AUTOSAR XML (schema 00046)
package /ComponentTypes
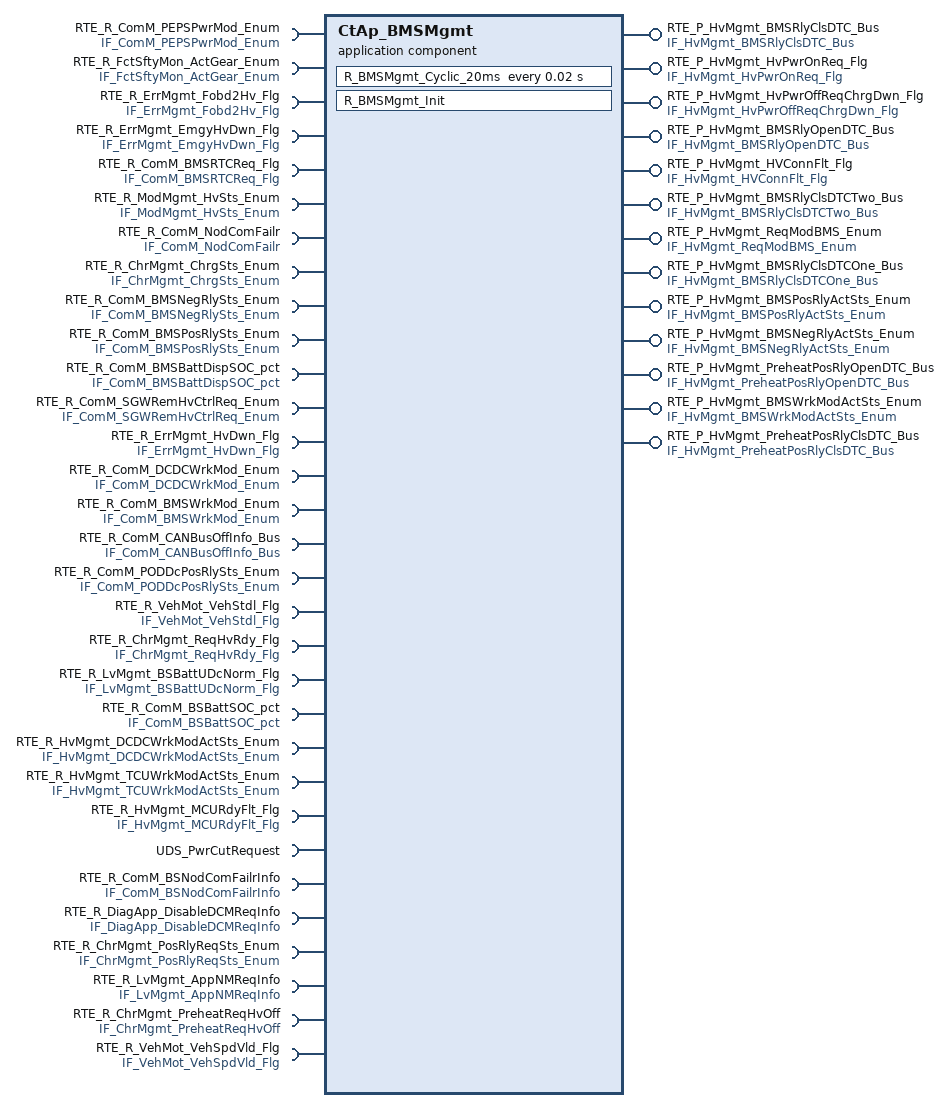
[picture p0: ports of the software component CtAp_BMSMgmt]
  application sw component type CtAp_BMSMgmt
    21 x require port:
      RTE_R_ComM_PEPSPwrMod_Enum: nonqueued-receiver-com-spec{data-element=tec_ComM_PEPSPwrMod_Enum, filter=data-filter-type=ALWAYS, init-value=0}, required-interface=IF_ComM_PEPSPwrMod_Enum
      RTE_R_FctSftyMon_ActGear_Enum: nonqueued-receiver-com-spec{data-element=tec_FctSftyMon_ActGear_Enum, filter=data-filter-type=ALWAYS, init-value=0}, required-interface=IF_FctSftyMon_ActGear_Enum
      RTE_R_ErrMgmt_Fobd2Hv_Flg: nonqueued-receiver-com-spec{data-element=tec_ErrMgmt_Fobd2Hv_Flg, filter=data-filter-type=ALWAYS, init-value=0}, required-interface=IF_ErrMgmt_Fobd2Hv_Flg
      RTE_R_ErrMgmt_EmgyHvDwn_Flg: nonqueued-receiver-com-spec{data-element=tec_ErrMgmt_EmgyHvDwn_Flg, filter=data-filter-type=ALWAYS, init-value=0}, required-interface=IF_ErrMgmt_EmgyHvDwn_Flg
      RTE_R_ComM_BMSRTCReq_Flg: nonqueued-receiver-com-spec{data-element=tec_ComM_BMSRTCReq_Flg, filter=data-filter-type=ALWAYS, init-value=0}, required-interface=IF_ComM_BMSRTCReq_Flg
      RTE_R_ModMgmt_HvSts_Enum: nonqueued-receiver-com-spec{data-element=tec_ModMgmt_HvSts_Enum, filter=data-filter-type=ALWAYS, init-value=0}, required-interface=IF_ModMgmt_HvSts_Enum
      RTE_R_ComM_NodComFailr: required-interface=IF_ComM_NodComFailr
        required-com-specs:
          data-element=tec_ComM_SGWNodComFailr_Flg, filter=data-filter-type=ALWAYS, init-value=0
          data-element=tec_ComM_CGWNodComFailr_Flg, filter=data-filter-type=ALWAYS, init-value=0
          data-element=tec_ComM_TCUNodComFailr_Flg, filter=data-filter-type=ALWAYS, init-value=0
          data-element=tec_ComM_BCMNodComFailr_Flg, filter=data-filter-type=ALWAYS, init-value=0
          data-element=tec_ComM_PRNDNodComFailr_Flg, filter=data-filter-type=ALWAYS, init-value=0
          data-element=tec_ComM_IVINodComFailr_Flg, filter=data-filter-type=ALWAYS, init-value=0
          data-element=tec_ComM_DCDCNodComFailr_Flg, filter=data-filter-type=ALWAYS, init-value=0
          data-element=tec_ComM_OBCNodComFailr_Flg, filter=data-filter-type=ALWAYS, init-value=0
          data-element=tec_ComM_CHIBSNodComFailr_Flg, filter=data-filter-type=ALWAYS, init-value=0
          data-element=tec_ComM_MCUNodComFailr_Flg, filter=data-filter-type=ALWAYS, init-value=0
          data-element=tec_ComM_EVCOMNodComFailr_Flg, filter=data-filter-type=ALWAYS, init-value=0
          data-element=tec_ComM_EPTIBSNodComFailr_Flg, filter=data-filter-type=ALWAYS, init-value=0
          data-element=tec_ComM_DCMNodComFailr_Flg, filter=data-filter-type=ALWAYS, init-value=0
          data-element=tec_ComM_BMSNodComFailr_Flg, filter=data-filter-type=ALWAYS, init-value=0
          data-element=tec_ComM_ACUNodComFailr_Flg, filter=data-filter-type=ALWAYS, init-value=0
          data-element=tec_ComM_APTCNodComFailr_Flg, filter=data-filter-type=ALWAYS, init-value=0
          data-element=tec_ComM_ADCUNodComFailr_Flg, filter=data-filter-type=ALWAYS, init-value=0
          data-element=tec_ComM_DCMRRNodComFailr_Flg, filter=data-filter-type=ALWAYS, init-value=0
          data-element=tec_ComM_DCMRLNodComFailr_Flg, filter=data-filter-type=ALWAYS, init-value=0
          data-element=tec_ComM_DCMFRNodComFailr_Flg, filter=data-filter-type=ALWAYS, init-value=0
          data-element=tec_ComM_DCMFLNodComFailr_Flg, filter=data-filter-type=ALWAYS, init-value=0
          data-element=tec_ComM_SGWCHNodComFailr_Flg, init-value=0
      RTE_R_ChrMgmt_ChrgSts_Enum: nonqueued-receiver-com-spec{data-element=tec_ChrMgmt_ChrgSts_Enum, filter=data-filter-type=ALWAYS, init-value=0}, required-interface=IF_ChrMgmt_ChrgSts_Enum
      RTE_R_ComM_BMSNegRlySts_Enum: nonqueued-receiver-com-spec{data-element=tec_ComM_BMSNegRlySts_Enum, filter=data-filter-type=ALWAYS, init-value=0}, required-interface=IF_ComM_BMSNegRlySts_Enum
      RTE_R_ComM_BMSPosRlySts_Enum: nonqueued-receiver-com-spec{data-element=tec_ComM_BMSPosRlySts_Enum, filter=data-filter-type=ALWAYS, init-value=0}, required-interface=IF_ComM_BMSPosRlySts_Enum
      RTE_R_ComM_BMSBattDispSOC_pct: nonqueued-receiver-com-spec{data-element=tec_ComM_BMSBattDispSOC_pct, filter=data-filter-type=ALWAYS, init-value=0}, required-interface=IF_ComM_BMSBattDispSOC_pct
      RTE_R_ComM_SGWRemHvCtrlReq_Enum: nonqueued-receiver-com-spec{data-element=tec_ComM_SGWRemHvCtrlReq_Enum, filter=data-filter-type=ALWAYS, init-value=0}, required-interface=IF_ComM_SGWRemHvCtrlReq_Enum
      RTE_R_ErrMgmt_HvDwn_Flg: nonqueued-receiver-com-spec{data-element=tec_ErrMgmt_HvDwn_Flg, filter=data-filter-type=ALWAYS, init-value=0}, required-interface=IF_ErrMgmt_HvDwn_Flg
      RTE_R_ComM_DCDCWrkMod_Enum: nonqueued-receiver-com-spec{data-element=tec_ComM_DCDCWrkMod_Enum, filter=data-filter-type=ALWAYS, init-value=0}, required-interface=IF_ComM_DCDCWrkMod_Enum
      RTE_R_ComM_BMSWrkMod_Enum: nonqueued-receiver-com-spec{data-element=tec_ComM_BMSWrkMod_Enum, filter=data-filter-type=ALWAYS, init-value=0}, required-interface=IF_ComM_BMSWrkMod_Enum
      RTE_R_ComM_CANBusOffInfo_Bus: required-interface=IF_ComM_CANBusOffInfo_Bus
        required-com-specs:
          data-element=tec_ComM_EPTCANBusOffInfo_Bus, filter=data-filter-type=ALWAYS, init-value=fields=[ComM_MonStatEPTCANBusOffInfo:0, ComM_MonResEPTCANBusOffInfo:0, ComM_ErrStatEPTCANBusOffInfo:0, ComM_ErrResEPTCANBusOffInfo:0]
          data-element=tec_ComM_CHCANBusOffInfo_Bus, filter=data-filter-type=ALWAYS, init-value=fields=[ComM_MonStatCHCANBusOffInfo:0, ComM_MonResCHCANBusOffInfo:0, ComM_ErrStatCHCANBusOffInfo:0, ComM_ErrResCHCANBusOffInfo:0]
          data-element=tec_ComM_EPTCANBusOffDTCInfo_Bus, filter=data-filter-type=ALWAYS, init-value=fields=[ComM_MonStatEPTCANBusOffDTCInfo:0, ComM_MonResEPTCANBusOffDTCInfo:0, ComM_ErrStatEPTCANBusOffDTCInfo:0, ComM_ErrResEPTCANBusOffDTCInfo:0]
          data-element=tec_ComM_CHCANBusOffDTCInfo_Bus, filter=data-filter-type=ALWAYS, init-value=fields=[ComM_MonStatCHCANBusOffDTCInfo:0, ComM_MonResCHCANBusOffDTCInfo:0, ComM_ErrStatCHCANBusOffDTCInfo:0, ComM_ErrResCHCANBusOffDTCInfo:0]
          data-element=tec_ComM_DCCANBusOffDTCInfo_Bus, init-value=fields=[ComM_MonStatDCCANDTCBusOffInfo:0, ComM_MonResDCCANDTCBusOffInfo:0, ComM_ErrStatDCCANDTCBusOffInfo:0, ComM_ErrResDCCANDTCBusOffInfo:0]
          data-element=tec_ComM_DCCANBusOffInfo_Bus, init-value=fields=[ComM_MonStatDCCANBusOffInfo:0, ComM_MonResDCCANBusOffInfo:0, ComM_ErrStatDCCANBusOffInfo:0, ComM_ErrResDCCANBusOffInfo:0]
      RTE_R_ComM_PODDcPosRlySts_Enum: nonqueued-receiver-com-spec{data-element=tec_ComM_PODDcPosRlySts_Enum, filter=data-filter-type=ALWAYS, init-value=0}, required-interface=IF_ComM_PODDcPosRlySts_Enum
      RTE_R_VehMot_VehStdl_Flg: nonqueued-receiver-com-spec{data-element=tec_VehMot_VehStdl_Flg, filter=data-filter-type=ALWAYS, init-value=0}, required-interface=IF_VehMot_VehStdl_Flg
      RTE_R_ChrMgmt_ReqHvRdy_Flg: nonqueued-receiver-com-spec{data-element=tec_ChrMgmt_ReqHvRdy_Flg, filter=data-filter-type=ALWAYS, init-value=0}, required-interface=IF_ChrMgmt_ReqHvRdy_Flg
      RTE_R_LvMgmt_BSBattUDcNorm_Flg: nonqueued-receiver-com-spec{data-element=tec_LvMgmt_BSBattUDcNorm_Flg, filter=data-filter-type=ALWAYS, init-value=0}, required-interface=IF_LvMgmt_BSBattUDcNorm_Flg
      RTE_R_ComM_BSBattSOC_pct: nonqueued-receiver-com-spec{data-element=tec_ComM_BSBattSOC_pct, filter=data-filter-type=ALWAYS, init-value=0}, required-interface=IF_ComM_BSBattSOC_pct
    13 x provide port:
      RTE_P_HvMgmt_BMSRlyClsDTC_Bus: nonqueued-sender-com-spec{data-element=tec_HvMgmt_BMSRlyClsDTC_Bus, init-value=fields=[HvMgmt_MonStatBMSRlyClsDTC:0, HvMgmt_MonResBMSRlyClsDTC:0, HvMgmt_ErrStatBMSRlyClsDTC:0, HvMgmt_ErrResBMSRlyClsDTC:0]}, provided-interface=IF_HvMgmt_BMSRlyClsDTC_Bus
      RTE_P_HvMgmt_HvPwrOnReq_Flg: nonqueued-sender-com-spec{data-element=tec_HvMgmt_HvPwrOnReq_Flg, init-value=0}, provided-interface=IF_HvMgmt_HvPwrOnReq_Flg
      RTE_P_HvMgmt_HvPwrOffReqChrgDwn_Flg: nonqueued-sender-com-spec{data-element=tec_HvMgmt_HvPwrOffReqChrgDwn_Flg, init-value=0}, provided-interface=IF_HvMgmt_HvPwrOffReqChrgDwn_Flg
      RTE_P_HvMgmt_BMSRlyOpenDTC_Bus: nonqueued-sender-com-spec{data-element=tec_HvMgmt_BMSRlyOpenDTC_Bus, init-value=fields=[HvMgmt_MonStatBMSRlyOpenDTC:0, HvMgmt_MonResBMSRlyOpenDTC:0, HvMgmt_ErrStatBMSRlyOpenDTC:0, HvMgmt_ErrResBMSRlyOpenDTC:0]}, provided-interface=IF_HvMgmt_BMSRlyOpenDTC_Bus
      RTE_P_HvMgmt_HVConnFlt_Flg: nonqueued-sender-com-spec{data-element=tec_HvMgmt_HVConnFlt_Flg, init-value=0}, provided-interface=IF_HvMgmt_HVConnFlt_Flg
      RTE_P_HvMgmt_BMSRlyClsDTCTwo_Bus: nonqueued-sender-com-spec{data-element=tec_HvMgmt_BMSRlyClsDTCTwo_Bus, init-value=fields=[HvMgmt_MonStatBMSRlyClsDTCTwo:0, HvMgmt_MonResBMSRlyClsDTCTwo:0, HvMgmt_ErrStatBMSRlyClsDTCTwo:0, HvMgmt_ErrResBMSRlyClsDTCTwo:0]}, provided-interface=IF_HvMgmt_BMSRlyClsDTCTwo_Bus
      RTE_P_HvMgmt_ReqModBMS_Enum: nonqueued-sender-com-spec{data-element=tec_HvMgmt_ReqModBMS_Enum, init-value=0}, provided-interface=IF_HvMgmt_ReqModBMS_Enum
      RTE_P_HvMgmt_BMSRlyClsDTCOne_Bus: nonqueued-sender-com-spec{data-element=tec_HvMgmt_BMSRlyClsDTCOne_Bus, init-value=fields=[HvMgmt_MonStatBMSRlyClsDTCOne:0, HvMgmt_MonResBMSRlyClsDTCOne:0, HvMgmt_ErrStatBMSRlyClsDTCOne:0, HvMgmt_ErrResBMSRlyClsDTCOne:0]}, provided-interface=IF_HvMgmt_BMSRlyClsDTCOne_Bus
      RTE_P_HvMgmt_BMSPosRlyActSts_Enum: nonqueued-sender-com-spec{data-element=tec_HvMgmt_BMSPosRlyActSts_Enum, init-value=0}, provided-interface=IF_HvMgmt_BMSPosRlyActSts_Enum
      RTE_P_HvMgmt_BMSNegRlyActSts_Enum: nonqueued-sender-com-spec{data-element=tec_HvMgmt_BMSNegRlyActSts_Enum, init-value=0}, provided-interface=IF_HvMgmt_BMSNegRlyActSts_Enum
      RTE_P_HvMgmt_PreheatPosRlyOpenDTC_Bus: nonqueued-sender-com-spec{data-element=tec_HvMgmt_PreheatPosRlyOpenDTC_Bus, init-value=fields=[HvMgmt_MonStatPreheatPosRlyOpenDTC:0, HvMgmt_MonResPreheatPosRlyOpenDTC:0, HvMgmt_ErrStatPreheatPosRlyOpenDTC:0, HvMgmt_ErrResPreheatPosRlyOpenDTC:0]}, provided-interface=IF_HvMgmt_PreheatPosRlyOpenDTC_Bus
      RTE_P_HvMgmt_BMSWrkModActSts_Enum: nonqueued-sender-com-spec{data-element=tec_HvMgmt_BMSWrkModActSts_Enum, init-value=0}, provided-interface=IF_HvMgmt_BMSWrkModActSts_Enum
      RTE_P_HvMgmt_PreheatPosRlyClsDTC_Bus: nonqueued-sender-com-spec{data-element=tec_HvMgmt_PreheatPosRlyClsDTC_Bus, init-value=fields=[HvMgmt_MonStatPreheatPosRlyClsDTC:0, HvMgmt_MonResPreheatPosRlyClsDTC:0, HvMgmt_ErrStatPreheatPosRlyClsDTC:0, HvMgmt_ErrResPreheatPosRlyClsDTC:0]}, provided-interface=IF_HvMgmt_PreheatPosRlyClsDTC_Bus
    10 x require port:
      RTE_R_HvMgmt_DCDCWrkModActSts_Enum: nonqueued-receiver-com-spec{data-element=tec_HvMgmt_DCDCWrkModActSts_Enum, filter=data-filter-type=ALWAYS, init-value=0}, required-interface=IF_HvMgmt_DCDCWrkModActSts_Enum
      RTE_R_HvMgmt_TCUWrkModActSts_Enum: nonqueued-receiver-com-spec{data-element=tec_HvMgmt_TCUWrkModActSts_Enum, filter=data-filter-type=ALWAYS, init-value=0}, required-interface=IF_HvMgmt_TCUWrkModActSts_Enum
      RTE_R_HvMgmt_MCURdyFlt_Flg: nonqueued-receiver-com-spec{data-element=tec_HvMgmt_MCURdyFlt_Flg, filter=data-filter-type=ALWAYS, init-value=0}, required-interface=IF_HvMgmt_MCURdyFlt_Flg
      UDS_PwrCutRequest: nonqueued-receiver-com-spec{data-element=PwrCutRequest, filter=data-filter-type=ALWAYS, init-value=0}, required-interface=UDS_PwrCutRequest
      RTE_R_ComM_BSNodComFailrInfo: nonqueued-receiver-com-spec{data-element=tec_ComM_BSNodComFailrInfo, filter=data-filter-type=ALWAYS, init-value=0}, required-interface=IF_ComM_BSNodComFailrInfo
      RTE_R_DiagApp_DisableDCMReqInfo: nonqueued-receiver-com-spec{data-element=tec_DiagApp_DisableDCMReqInfo, filter=data-filter-type=ALWAYS, init-value=0}, required-interface=IF_DiagApp_DisableDCMReqInfo
      RTE_R_ChrMgmt_PosRlyReqSts_Enum: nonqueued-receiver-com-spec{data-element=tec_ChrMgmt_PosRlyReqSts_Enum, filter=data-filter-type=ALWAYS, init-value=0}, required-interface=IF_ChrMgmt_PosRlyReqSts_Enum
      RTE_R_LvMgmt_AppNMReqInfo: nonqueued-receiver-com-spec{data-element=tec_LvMgmt_AppNMReqInfo, filter=data-filter-type=ALWAYS, init-value=0}, required-interface=IF_LvMgmt_AppNMReqInfo
      RTE_R_ChrMgmt_PreheatReqHvOff: nonqueued-receiver-com-spec{data-element=tec_ChrMgmt_PreheatReqHvOff, filter=data-filter-type=ALWAYS, init-value=0}, required-interface=IF_ChrMgmt_PreheatReqHvOff
      RTE_R_VehMot_VehSpdVld_Flg: nonqueued-receiver-com-spec{data-element=tec_VehMot_VehSpdVld_Flg, filter=data-filter-type=ALWAYS, init-value=0}, required-interface=IF_VehMot_VehSpdVld_Flg
    behavior CtAp_BMSMgmt_InternalBehavior
      timing event TMT_R_BMSMgmt_Cyclic_20ms: start-on-event=R_BMSMgmt_Cyclic_20ms, period=0.02
      init event CtAp_BMSMgmt_InitEvent: start-on-event=R_BMSMgmt_Init
      runnable R_BMSMgmt_Cyclic_20ms
        data-receive-point-by-arguments:
          34 x access:
            REC_RTE_R_ChrMgmt_ChrgSts_Enum_tec_ChrMgmt_ChrgSts_Enum: accessed-variable=RTE_R_ChrMgmt_ChrgSts_Enum.tec_ChrMgmt_ChrgSts_Enum
            REC_RTE_R_ChrMgmt_ReqHvRdy_Flg_tec_ChrMgmt_ReqHvRdy_Flg: accessed-variable=RTE_R_ChrMgmt_ReqHvRdy_Flg.tec_ChrMgmt_ReqHvRdy_Flg
            REC_RTE_R_ComM_BMSBattDispSOC_pct_tec_ComM_BMSBattDispSOC_pct: accessed-variable=RTE_R_ComM_BMSBattDispSOC_pct.tec_ComM_BMSBattDispSOC_pct
            REC_RTE_R_ComM_BMSNegRlySts_Enum_tec_ComM_BMSNegRlySts_Enum: accessed-variable=RTE_R_ComM_BMSNegRlySts_Enum.tec_ComM_BMSNegRlySts_Enum
            REC_RTE_R_ComM_BMSPosRlySts_Enum_tec_ComM_BMSPosRlySts_Enum: accessed-variable=RTE_R_ComM_BMSPosRlySts_Enum.tec_ComM_BMSPosRlySts_Enum
            REC_RTE_R_ComM_BMSRTCReq_Flg_tec_ComM_BMSRTCReq_Flg: accessed-variable=RTE_R_ComM_BMSRTCReq_Flg.tec_ComM_BMSRTCReq_Flg
            REC_RTE_R_ComM_BMSWrkMod_Enum_tec_ComM_BMSWrkMod_Enum: accessed-variable=RTE_R_ComM_BMSWrkMod_Enum.tec_ComM_BMSWrkMod_Enum
            REC_RTE_R_ComM_BSBattSOC_pct_tec_ComM_BSBattSOC_pct: accessed-variable=RTE_R_ComM_BSBattSOC_pct.tec_ComM_BSBattSOC_pct
            REC_RTE_R_ComM_CANBusOffInfo_Bus_tec_ComM_EPTCANBusOffInfo_Bus: accessed-variable=RTE_R_ComM_CANBusOffInfo_Bus.tec_ComM_EPTCANBusOffInfo_Bus
            REC_RTE_R_ComM_DCDCWrkMod_Enum_tec_ComM_DCDCWrkMod_Enum: accessed-variable=RTE_R_ComM_DCDCWrkMod_Enum.tec_ComM_DCDCWrkMod_Enum
            REC_RTE_R_ComM_NodComFailr_tec_ComM_BCMNodComFailr_Flg: accessed-variable=RTE_R_ComM_NodComFailr.tec_ComM_BCMNodComFailr_Flg
            REC_RTE_R_ComM_NodComFailr_tec_ComM_BMSNodComFailr_Flg: accessed-variable=RTE_R_ComM_NodComFailr.tec_ComM_BMSNodComFailr_Flg
            REC_RTE_R_ComM_NodComFailr_tec_ComM_MCUNodComFailr_Flg: accessed-variable=RTE_R_ComM_NodComFailr.tec_ComM_MCUNodComFailr_Flg
            REC_RTE_R_ComM_NodComFailr_tec_ComM_SGWNodComFailr_Flg: accessed-variable=RTE_R_ComM_NodComFailr.tec_ComM_SGWNodComFailr_Flg
            REC_RTE_R_ComM_PEPSPwrMod_Enum_tec_ComM_PEPSPwrMod_Enum: accessed-variable=RTE_R_ComM_PEPSPwrMod_Enum.tec_ComM_PEPSPwrMod_Enum
            REC_RTE_R_ComM_PODDcPosRlySts_Enum_tec_ComM_PODDcPosRlySts_Enum: accessed-variable=RTE_R_ComM_PODDcPosRlySts_Enum.tec_ComM_PODDcPosRlySts_Enum
            REC_RTE_R_ComM_SGWRemHvCtrlReq_Enum_tec_ComM_SGWRemHvCtrlReq_Enum: accessed-variable=RTE_R_ComM_SGWRemHvCtrlReq_Enum.tec_ComM_SGWRemHvCtrlReq_Enum
            REC_RTE_R_ErrMgmt_EmgyHvDwn_Flg_tec_ErrMgmt_EmgyHvDwn_Flg: accessed-variable=RTE_R_ErrMgmt_EmgyHvDwn_Flg.tec_ErrMgmt_EmgyHvDwn_Flg
            REC_RTE_R_ErrMgmt_Fobd2Hv_Flg_tec_ErrMgmt_Fobd2Hv_Flg: accessed-variable=RTE_R_ErrMgmt_Fobd2Hv_Flg.tec_ErrMgmt_Fobd2Hv_Flg
            REC_RTE_R_ErrMgmt_HvDwn_Flg_tec_ErrMgmt_HvDwn_Flg: accessed-variable=RTE_R_ErrMgmt_HvDwn_Flg.tec_ErrMgmt_HvDwn_Flg
            REC_RTE_R_FctSftyMon_ActGear_Enum_tec_FctSftyMon_ActGear_Enum: accessed-variable=RTE_R_FctSftyMon_ActGear_Enum.tec_FctSftyMon_ActGear_Enum
            REC_RTE_R_HvMgmt_DCDCWrkModActSts_Enum_tec_HvMgmt_DCDCWrkModActSts_Enum: accessed-variable=RTE_R_HvMgmt_DCDCWrkModActSts_Enum.tec_HvMgmt_DCDCWrkModActSts_Enum
            REC_RTE_R_HvMgmt_MCURdyFlt_Flg_tec_HvMgmt_MCURdyFlt_Flg: accessed-variable=RTE_R_HvMgmt_MCURdyFlt_Flg.tec_HvMgmt_MCURdyFlt_Flg
            REC_RTE_R_HvMgmt_TCUWrkModActSts_Enum_tec_HvMgmt_TCUWrkModActSts_Enum: accessed-variable=RTE_R_HvMgmt_TCUWrkModActSts_Enum.tec_HvMgmt_TCUWrkModActSts_Enum
            REC_RTE_R_LvMgmt_BSBattUDcNorm_Flg_tec_LvMgmt_BSBattUDcNorm_Flg: accessed-variable=RTE_R_LvMgmt_BSBattUDcNorm_Flg.tec_LvMgmt_BSBattUDcNorm_Flg
            REC_RTE_R_ModMgmt_HvSts_Enum_tec_ModMgmt_HvSts_Enum: accessed-variable=RTE_R_ModMgmt_HvSts_Enum.tec_ModMgmt_HvSts_Enum
            REC_RTE_R_VehMot_VehStdl_Flg_tec_VehMot_VehStdl_Flg: accessed-variable=RTE_R_VehMot_VehStdl_Flg.tec_VehMot_VehStdl_Flg
            REC_UDS_PwrCutRequest_PwrCutRequest: accessed-variable=UDS_PwrCutRequest.PwrCutRequest
            REC_RTE_R_ComM_BSNodComFailrInfo_tec_ComM_BSNodComFailrInfo: accessed-variable=RTE_R_ComM_BSNodComFailrInfo.tec_ComM_BSNodComFailrInfo
            REC_RTE_R_DiagApp_DisableDCMReqInfo_tec_DiagApp_DisableDCMReqInfo: accessed-variable=RTE_R_DiagApp_DisableDCMReqInfo.tec_DiagApp_DisableDCMReqInfo
            REC_RTE_R_ChrMgmt_PosRlyReqSts_Enum_tec_ChrMgmt_PosRlyReqSts_Enum: accessed-variable=RTE_R_ChrMgmt_PosRlyReqSts_Enum.tec_ChrMgmt_PosRlyReqSts_Enum
            REC_RTE_R_LvMgmt_AppNMReqInfo_tec_LvMgmt_AppNMReqInfo: accessed-variable=RTE_R_LvMgmt_AppNMReqInfo.tec_LvMgmt_AppNMReqInfo
            REC_RTE_R_ChrMgmt_PreheatReqHvOff_tec_ChrMgmt_PreheatReqHvOff: accessed-variable=RTE_R_ChrMgmt_PreheatReqHvOff.tec_ChrMgmt_PreheatReqHvOff
            REC_RTE_R_VehMot_VehSpdVld_Flg_tec_VehMot_VehSpdVld_Flg: accessed-variable=RTE_R_VehMot_VehSpdVld_Flg.tec_VehMot_VehSpdVld_Flg
        data-send-points:
          13 x access:
            SEND_RTE_P_HvMgmt_BMSClsDTCOne_Bus_tec_HvMgmt_BMSRlyClsDTCOne_Bus: accessed-variable=RTE_P_HvMgmt_BMSRlyClsDTCOne_Bus.tec_HvMgmt_BMSRlyClsDTCOne_Bus
            SEND_RTE_P_HvMgmt_BMSClsDTCTwo_Bus_tec_HvMgmt_BMSRlyClsDTCTwo_Bus: accessed-variable=RTE_P_HvMgmt_BMSRlyClsDTCTwo_Bus.tec_HvMgmt_BMSRlyClsDTCTwo_Bus
            SEND_RTE_P_HvMgmt_BMSClsDTC_Bus_tec_HvMgmt_BMSRlyClsDTC_Bus: accessed-variable=RTE_P_HvMgmt_BMSRlyClsDTC_Bus.tec_HvMgmt_BMSRlyClsDTC_Bus
            SEND_RTE_P_HvMgmt_BMSNegRlyActSts_Enum_tec_HvMgmt_BMSNegRlyActSts_Enum: accessed-variable=RTE_P_HvMgmt_BMSNegRlyActSts_Enum.tec_HvMgmt_BMSNegRlyActSts_Enum
            SEND_RTE_P_HvMgmt_BMSOpenDTC_Bus_tec_HvMgmt_BMSRlyOpenDTC_Bus: accessed-variable=RTE_P_HvMgmt_BMSRlyOpenDTC_Bus.tec_HvMgmt_BMSRlyOpenDTC_Bus
            SEND_RTE_P_HvMgmt_BMSPosRlyActSts_Enum_tec_HvMgmt_BMSPosRlyActSts_Enum: accessed-variable=RTE_P_HvMgmt_BMSPosRlyActSts_Enum.tec_HvMgmt_BMSPosRlyActSts_Enum
            SEND_RTE_P_HvMgmt_BMSWrkModActSts_Enum_tec_HvMgmt_BMSWrkModActSts_Enum: accessed-variable=RTE_P_HvMgmt_BMSWrkModActSts_Enum.tec_HvMgmt_BMSWrkModActSts_Enum
            SEND_RTE_P_HvMgmt_HVConnFlt_Flg_tec_HvMgmt_HVConnFlt_Flg: accessed-variable=RTE_P_HvMgmt_HVConnFlt_Flg.tec_HvMgmt_HVConnFlt_Flg
            SEND_RTE_P_HvMgmt_HvPwrOffReqChrgDwn_Flg_tec_HvMgmt_HvPwrOffReqChrgDwn_Flg: accessed-variable=RTE_P_HvMgmt_HvPwrOffReqChrgDwn_Flg.tec_HvMgmt_HvPwrOffReqChrgDwn_Flg
            SEND_RTE_P_HvMgmt_HvPwrOnReq_Flg_tec_HvMgmt_HvPwrOnReq_Flg: accessed-variable=RTE_P_HvMgmt_HvPwrOnReq_Flg.tec_HvMgmt_HvPwrOnReq_Flg
            SEND_RTE_P_HvMgmt_PreheatPosRlyClsDTC_Bus_tec_HvMgmt_PreheatPosRlyClsDTC_Bus: accessed-variable=RTE_P_HvMgmt_PreheatPosRlyClsDTC_Bus.tec_HvMgmt_PreheatPosRlyClsDTC_Bus
            SEND_RTE_P_HvMgmt_PreheatPosRlyOpenDTC_Bus_tec_HvMgmt_PreheatPosRlyOpenDTC_Bus: accessed-variable=RTE_P_HvMgmt_PreheatPosRlyOpenDTC_Bus.tec_HvMgmt_PreheatPosRlyOpenDTC_Bus
            SEND_RTE_P_HvMgmt_ReqModBMS_Enum_tec_HvMgmt_ReqModBMS_Enum: accessed-variable=RTE_P_HvMgmt_ReqModBMS_Enum.tec_HvMgmt_ReqModBMS_Enum
      runnable R_BMSMgmt_Init
  swc implementation CtAp_BMSMgmt_Implementation: behavior=CtAp_BMSMgmt_InternalBehavior
